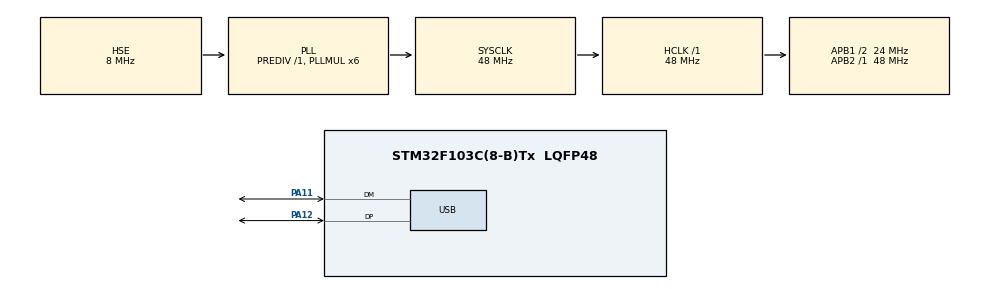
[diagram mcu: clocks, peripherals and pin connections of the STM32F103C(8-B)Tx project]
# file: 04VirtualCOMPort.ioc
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Mcu.Family=STM32F1
Mcu.Name=STM32F103C(8-B)Tx
Mcu.Package=LQFP48
NVIC.PriorityGroup=NVIC_PRIORITYGROUP_4
NVIC.USB_LP_CAN1_RX0_IRQn=true\:0\:0\:false\:false\:true\:false\:true\:true
PA11.Mode=Device
PA11.Signal=USB_DM
PA12.Mode=Device
PA12.Signal=USB_DP
PA13.Mode=Serial_Wire
PA13.Signal=SYS_JTMS-SWDIO
PA14.Mode=Serial_Wire
PA14.Signal=SYS_JTCK-SWCLK
PD0-OSC_IN.Mode=HSE-External-Oscillator
PD0-OSC_IN.Signal=RCC_OSC_IN
PD1-OSC_OUT.Mode=HSE-External-Oscillator
PD1-OSC_OUT.Signal=RCC_OSC_OUT
ProjectManager.HeapSize=0x200
ProjectManager.StackSize=0x400
ProjectManager.TargetToolchain=CMake
RCC.AHBFreq_Value=48000000
RCC.APB1CLKDivider=RCC_HCLK_DIV2
RCC.APB1Freq_Value=24000000
RCC.APB1TimFreq_Value=48000000
RCC.APB2Freq_Value=48000000
RCC.APB2TimFreq_Value=48000000
RCC.HCLKFreq_Value=48000000
RCC.PLLMUL=RCC_PLL_MUL6
RCC.SYSCLKFreq_VALUE=48000000
RCC.SYSCLKSource=RCC_SYSCLKSOURCE_PLLCLK
RCC.USBFreq_Value=48000000
USB_DEVICE.CLASS_NAME_FS=CDC
USB_DEVICE.VirtualMode=Cdc
USB_DEVICE.VirtualModeFS=Cdc_FS
VP_USB_DEVICE_VS_USB_DEVICE_CDC_FS.Mode=CDC_FS
board=custom

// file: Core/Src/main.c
/* USER CODE BEGIN Header */
/**
  ******************************************************************************
  * @file           : main.c
  * @brief          : Main program body
  ******************************************************************************
  * @attention
  *
  * Copyright (c) 2026 STMicroelectronics.
  * All rights reserved.
  *
  * This software is licensed under terms that can be found in the LICENSE file
  * in the root directory of this software component.
  * If no LICENSE file comes with this software, it is provided AS-IS.
  *
  ******************************************************************************
  */
/* USER CODE END Header */
#include "main.h"
#include "usb_device.h"

/* USER CODE BEGIN Includes */

#include "usbd_cdc_if.h"
#include <stdio.h>
#include <string.h>

/* USER CODE END Includes */

/* USER CODE BEGIN PV */

static uint32_t s_lastHeartbeatTick = 0;
static uint32_t s_heartbeatCounter = 0;

/* USER CODE END PV */

void SystemClock_Config(void);
static void MX_GPIO_Init(void);
/* USER CODE BEGIN PFP */

static uint8_t USB_SendString(const char *text);
static void USB_ProcessCommand(char *cmdLine);

/* USER CODE END PFP */

/* USER CODE BEGIN 0 */

static uint8_t USB_SendString(const char *text)
{
  uint16_t len = (uint16_t)strlen(text);
  uint32_t startTick = HAL_GetTick();

  while (CDC_Transmit_FS((uint8_t *)text, len) == USBD_BUSY)
  {
    if ((HAL_GetTick() - startTick) > 100)
    {
      return USBD_BUSY;
    }
    HAL_Delay(1);
  }

  return USBD_OK;
}

static void USB_ProcessCommand(char *cmdLine)
{
  size_t len = strlen(cmdLine);
  const char *echoText;
  char txBuf[160];

  while (len > 0 && (cmdLine[len - 1] == '\r' || cmdLine[len - 1] == '\n'))
  {
    cmdLine[len - 1] = '\0';
    len--;
  }

  if (len == 0)
  {
    return;
  }

  if (strcmp(cmdLine, "help") == 0)
  {
    USB_SendString("Commands: help, ping, status, dice, echo <text>\r\n");
  }
  else if (strcmp(cmdLine, "ping") == 0)
  {
    USB_SendString("pong\r\n");
  }
  else if (strcmp(cmdLine, "status") == 0)
  {
    int n = snprintf(txBuf, sizeof(txBuf),
                     "Uptime: %lu ms, Heartbeat: %lu\r\n",
                     HAL_GetTick(), s_heartbeatCounter);
    if (n > 0)
    {
      USB_SendString(txBuf);
    }
  }
  else if (strcmp(cmdLine, "dice") == 0)
  {
    uint32_t diceValue = (HAL_GetTick() % 6UL) + 1UL;
    int n = snprintf(txBuf, sizeof(txBuf),
                     "Dice: %lu\r\n", diceValue);
    if (n > 0)
    {
      USB_SendString(txBuf);
    }
  }
  else if (strncmp(cmdLine, "echo ", 5) == 0)
  {
    echoText = &cmdLine[5];
    if (*echoText == '\0')
    {
      USB_SendString("Usage: echo <text>\r\n");
    }
    else
    {
      int n = snprintf(txBuf, sizeof(txBuf), "Echo: %s\r\n", echoText);
      if (n > 0)
      {
        USB_SendString(txBuf);
      }
    }
  }
  else
  {
    int n = snprintf(txBuf, sizeof(txBuf), "Unknown command: %s\r\n", cmdLine);
    if (n > 0)
    {
      USB_SendString(txBuf);
    }
  }
}

/* USER CODE END 0 */

int main(void)
{

  /* MCU Configuration--------------------------------------------------------*/

  /* Reset of all peripherals, Initializes the Flash interface and the Systick. */
  HAL_Init();

  /* Configure the system clock */
  SystemClock_Config();

  /* Initialize all configured peripherals */
  MX_GPIO_Init();
  MX_USB_DEVICE_Init();
  /* USER CODE BEGIN 2 */

  HAL_Delay(1200);
  USB_SendString("\r\n===== STM32 USB CDC Demo =====\r\n");
  USB_SendString("Type 'help' and press Enter.\r\n");

  /* USER CODE END 2 */

  /* Infinite loop */
  while (1)
  {

    /* USER CODE BEGIN 3 */
    if ((HAL_GetTick() - s_lastHeartbeatTick) >= 1000)
    {
      char heartbeatMsg[64];
      s_lastHeartbeatTick = HAL_GetTick();
      s_heartbeatCounter++;

      if ((s_heartbeatCounter % 5UL) == 0UL)
      {
        int n = snprintf(heartbeatMsg, sizeof(heartbeatMsg),
                         "Heartbeat %lu\r\n", s_heartbeatCounter);
        if (n > 0)
        {
          USB_SendString(heartbeatMsg);
        }
      }
    }

    if (g_usbRxFlag != 0U)
    {
      uint32_t rxLen;
      char cmdBuf[APP_RX_DATA_SIZE + 1U];

      __disable_irq();
      rxLen = g_usbRxLength;
      if (rxLen > APP_RX_DATA_SIZE)
      {
        rxLen = APP_RX_DATA_SIZE;
      }
      memcpy(cmdBuf, g_usbRxBuffer, rxLen);
      g_usbRxFlag = 0U;
      g_usbRxLength = 0U;
      __enable_irq();

      cmdBuf[rxLen] = '\0';
      USB_ProcessCommand(cmdBuf);
    }
  }
  /* USER CODE END 3 */
}

void SystemClock_Config(void)
{
  RCC_OscInitTypeDef RCC_OscInitStruct = {0};
  RCC_ClkInitTypeDef RCC_ClkInitStruct = {0};
  RCC_PeriphCLKInitTypeDef PeriphClkInit = {0};

  /** Initializes the RCC Oscillators according to the specified parameters
  * in the RCC_OscInitTypeDef structure.
  */
  RCC_OscInitStruct.OscillatorType = RCC_OSCILLATORTYPE_HSE;
  RCC_OscInitStruct.HSEState = RCC_HSE_ON;
  RCC_OscInitStruct.HSEPredivValue = RCC_HSE_PREDIV_DIV1;
  RCC_OscInitStruct.HSIState = RCC_HSI_ON;
  RCC_OscInitStruct.PLL.PLLState = RCC_PLL_ON;
  RCC_OscInitStruct.PLL.PLLSource = RCC_PLLSOURCE_HSE;
  RCC_OscInitStruct.PLL.PLLMUL = RCC_PLL_MUL6;
  if (HAL_RCC_OscConfig(&RCC_OscInitStruct) != HAL_OK)
  {
    Error_Handler();
  }

  /** Initializes the CPU, AHB and APB buses clocks
  */
  RCC_ClkInitStruct.ClockType = RCC_CLOCKTYPE_HCLK|RCC_CLOCKTYPE_SYSCLK
                              |RCC_CLOCKTYPE_PCLK1|RCC_CLOCKTYPE_PCLK2;
  RCC_ClkInitStruct.SYSCLKSource = RCC_SYSCLKSOURCE_PLLCLK;
  RCC_ClkInitStruct.AHBCLKDivider = RCC_SYSCLK_DIV1;
  RCC_ClkInitStruct.APB1CLKDivider = RCC_HCLK_DIV2;
  RCC_ClkInitStruct.APB2CLKDivider = RCC_HCLK_DIV1;

  if (HAL_RCC_ClockConfig(&RCC_ClkInitStruct, FLASH_LATENCY_1) != HAL_OK)
  {
    Error_Handler();
  }
  PeriphClkInit.PeriphClockSelection = RCC_PERIPHCLK_USB;
  PeriphClkInit.UsbClockSelection = RCC_USBCLKSOURCE_PLL;
  if (HAL_RCCEx_PeriphCLKConfig(&PeriphClkInit) != HAL_OK)
  {
    Error_Handler();
  }
}

static void MX_GPIO_Init(void)
{

  /* GPIO Ports Clock Enable */
  __HAL_RCC_GPIOD_CLK_ENABLE();
  __HAL_RCC_GPIOA_CLK_ENABLE();

}

void Error_Handler(void)
{
  __disable_irq();
  while (1)
  {
  }
}
